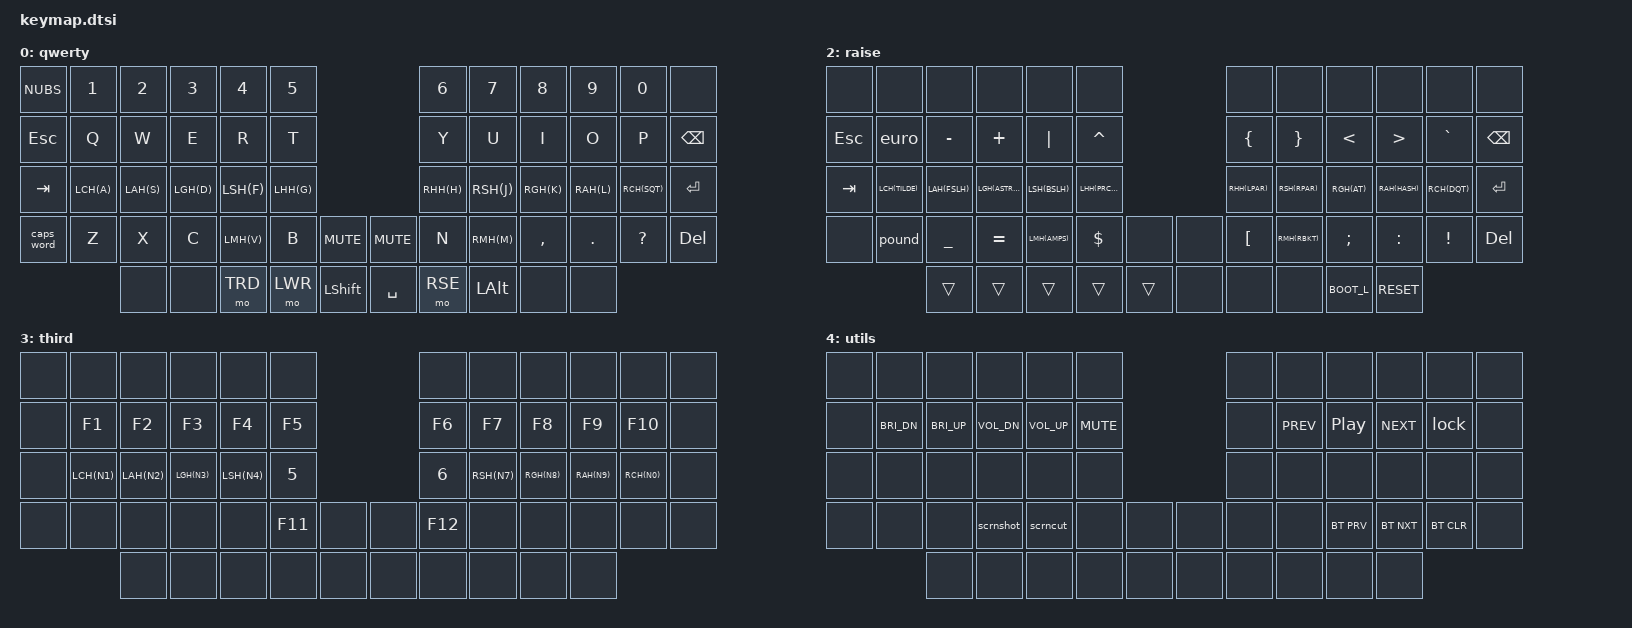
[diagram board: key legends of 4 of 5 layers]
/ {
    keymap {
        compatible = "zmk,keymap";
        qwerty {
            bindings = <
            /*╭───────────┬───────────┬───────────┬───────────┬───────────┬───────────╮                           ╭───────────┬───────────┬───────────┬───────────┬───────────┬───────────╮*/
            /*│     §     │     1     │     2     │     3     │     4     │     5     │                           │     6     │     7     │     8     │     9     │     0     │           │*/
                &kp NUBS    &kp N1      &kp N2      &kp N3      &kp N4      &kp N5    /*                         */ &kp N6      &kp N7      &kp N8      &kp N9      &kp N0      &none
            /*├───────────┼───────────┼───────────┼───────────┼───────────┼───────────┤                           ├───────────┼───────────┼───────────┼───────────┼───────────┼───────────┤*/
            /*│    esc    │     Q     │     W     │     E     │     R     │     T     │                           │     Y     │     U     │     I     │     O     │     P     │ backspace │*/
                &kp ESC     &kp Q       &kp W       &kp E       &kp R       &kp T     /*                         */ &kp Y       &kp U       &kp I       &kp O       &kp P       &kp BSPC
            /*├───────────┼───────────┼───────────┼───────────┼───────────┼───────────┤                           ├───────────┼───────────┼───────────┼───────────┼───────────┼───────────┤*/
            /*│    tab    │     A     │     S     │     D     │     F     │     G     ├───────────╮   ╭───────────┤     H     │     J     │     K     │     L     │     '     │   enter   │*/
                &kp TAB     LCH(A)      LAH(S)      LGH(D)      LSH(F)      LHH(G)    /* encoder */   /* encoder */ RHH(H)      RSH(J)      RGH(K)      RAH(L)      RCH(SQT)    &kp RET
            /*├───────────┼───────────┼───────────┼───────────┼───────────┼───────────┤           │   │           ├───────────┼───────────┼───────────┼───────────┼───────────┼───────────┤*/
            /*│ CAPS word │     Z     │     X     │     C     │     V     │     B     │   MUTE    │   │   MUTE    │     N     │     M     │     ,     │     .     │     ?     │  delete   │*/
                &caps_word  &kp Z       &kp X       &kp C       LMH(V)      &kp B       &kp MUTE  /* */ &kp MUTE    &kp N       RMH(M)      &kp COMMA   &kp DOT     &kp QMARK   &kp DEL
            /*╰───────────┴───────────┼───────────┼───────────┼───────────┼───────────┼───────────┤   ├───────────┼───────────┼───────────┼───────────┼───────────┼───────────┴───────────╯*/
            /*                        │           │           │           │           │   shift   │   │   space   │           │    alt    │           │           │                        */
                                        &none       &none       &mo TRD     &mo LWR     &kp LSHIFT/* */ &kp SPACE   &mo RSE     &kp LALT    &none       &none
            /*                        ╰───────────┴───────────┴───────────┴───────────┤           │   │           ├───────────┴───────────┴───────────┴───────────╯                        */
            /*                                                                        ╰───────────╯   ╰───────────╯                                                                        */
            >;

            sensor-bindings = <
                &inc_dec_kp BRI_DN BRI_UP &inc_dec_kp VOL_DN VOL_UP
            >;
        };
        lower {
            bindings = <
            /*╭───────────┬───────────┬───────────┬───────────┬───────────┬───────────╮                           ╭───────────┬───────────┬───────────┬───────────┬───────────┬───────────╮*/
            /*│           │           │           │           │           │           │                           │           │           │           │           │           │           │*/
                &none       &none       &none       &none       &none       &none     /*                         */ &none       &none       &none       &none       &none       &none
            /*├───────────┼───────────┼───────────┼───────────┼───────────┼───────────┤                           ├───────────┼───────────┼───────────┼───────────┼───────────┼───────────┤*/
            /*│           │           │           │           │           │           │                           │           │           │           │           │           │ backspace │*/
                &none       &kp BRI_DN  &kp BRI_UP  &kp VOL_DN  &kp VOL_UP  &kp MUTE  /*                         */ &none       &kp C_PREV  &kp C_PP    &kp C_NEXT  &lock       &kp BSPC
            /*├───────────┼───────────┼───────────┼───────────┼───────────┼───────────┤                           ├───────────┼───────────┼───────────┼───────────┼───────────┼───────────┤*/
            /*│           │    ctrl   │    alt    │    cmd    │   shift   │ CAPS word ├───────────╮   ╭───────────┤     <     │     v     │     ^     │     >     │           │   enter   │*/
                &none       &kp LCTRL   &kp LALT    &kp LGUI    &kp LSHIFT  &caps_word/* encoder */   /* encoder */ &kp LEFT    &kp DOWN    &kp UP      &kp RIGHT   &none       &kp RET
            /*├───────────┼───────────┼───────────┼───────────┼───────────┼───────────┤           │   │           ├───────────┼───────────┼───────────┼───────────┼───────────┼───────────┤*/
            /*│           │           │           │ screenshot│ screencut │           │           │   │           │ backspace │   enter   │    tab    │    esc    │   delete  │  delete   │*/
                &none       &none       &none       &scrnshot   &scrncut    RP          &none     /* */ &none       &kp BSPC    &kp RET     &kp TAB     &kp ESC     &kp DEL     &kp DEL
            /*╰───────────┴───────────┼───────────┼───────────┼───────────┼───────────┼───────────┤   ├───────────┼───────────┼───────────┼───────────┼───────────┼───────────┴───────────╯*/
            /*                        │   reset   │ bootloader│           │[activator]│           │   │   space   │           │           │           │           │                        */
                                        RESET       BOOT_L      &none       &none       &none     /* */ &kp SPACE   &trans      &trans      &trans      &trans
            /*                        ╰───────────┴───────────┴───────────┴───────────┤           │   │           ├───────────┴───────────┴───────────┴───────────╯                        */
            /*                                                                        ╰───────────╯   ╰───────────╯                                                                        */
            >;

            sensor-bindings = <
                &inc_dec_kp BRI_DN BRI_UP &inc_dec_kp VOL_DN VOL_UP
            >;
        };
        raise {
            bindings = <
            /*╭───────────┬───────────┬───────────┬───────────┬───────────┬───────────╮                           ╭───────────┬───────────┬───────────┬───────────┬───────────┬───────────╮*/
            /*│           │           │           │           │           │           │                           │           │           │           │           │           │           │*/
                &none       &none       &none       &none       &none       &none     /*                         */ &none       &none       &none       &none       &none       &none
            /*├───────────┼───────────┼───────────┼───────────┼───────────┼───────────┤                           ├───────────┼───────────┼───────────┼───────────┼───────────┼───────────┤*/
            /*│    esc    │     €     │     -     │     +     │     |     │     ^     │                           │     {     │     }     │     <     │     >     │     `     │ backspace │*/
                &kp ESC     &euro       &kp MINUS   &kp PLUS    &kp PIPE    &kp CARET /*                         */ &kp LBRC    &kp RBRC    &kp LT      &kp GT      &kp GRAVE   &kp BSPC
            /*├───────────┼───────────┼───────────┼───────────┼───────────┼───────────┤                           ├───────────┼───────────┼───────────┼───────────┼───────────┼───────────┤*/
            /*│    tab    │     ~     │     /     │     *     │     \     │     %     ├───────────╮   ╭───────────┤     (     │     )     │     @     │     #     │     "     │   enter   │*/
                &kp TAB     LCH(TILDE)  LAH(FSLH)   LGH(ASTRK)  LSH(BSLH)   LHH(PRCNT)/* encoder */   /* encoder */ RHH(LPAR)   RSH(RPAR)   RGH(AT)     RAH(HASH)   RCH(DQT)    &kp RET
            /*├───────────┼───────────┼───────────┼───────────┼───────────┼───────────┤           │   │           ├───────────┼───────────┼───────────┼───────────┼───────────┼───────────┤*/
            /*│           │     £     │     _     │     =     │     &     │     $     │           │   │           │     [     │     ]     │     ;     │     :     │     !     │  delete   │*/
                &none       &pound      &kp UNDER   &kp EQUAL   LMH(AMPS)   &kp DLLR    &none     /* */ &none       &kp LBKT    RMH(RBKT)   &kp SEMI    &kp COLON   &kp EXCL    &kp DEL
            /*╰───────────┴───────────┼───────────┼───────────┼───────────┼───────────┼───────────┤   ├───────────┼───────────┼───────────┼───────────┼───────────┼───────────┴───────────╯*/
            /*                        │           │           │           │           │           │   │           │[activator]│           │ bootloader│   reset   │                        */
                                        &trans      &trans      &trans      &trans      &trans    /* */ &none       &none       &none       BOOT_L      RESET
            /*                        ╰───────────┴───────────┴───────────┴───────────┤           │   │           ├───────────┴───────────┴───────────┴───────────╯                        */
            /*                                                                        ╰───────────╯   ╰───────────╯                                                                        */
            >;

            sensor-bindings = <
                &inc_dec_kp BRI_DN BRI_UP &inc_dec_kp C_PREV C_NEXT
            >;
        };
        third {
            bindings = <
            /*╭───────────┬───────────┬───────────┬───────────┬───────────┬───────────╮                           ╭───────────┬───────────┬───────────┬───────────┬───────────┬───────────╮*/
            /*│           │           │           │           │           │           │                           │           │           │           │           │           │           │*/
                &none       &none       &none       &none       &none       &none     /*                         */ &none       &none       &none       &none       &none       &none
            /*├───────────┼───────────┼───────────┼───────────┼───────────┼───────────┤                           ├───────────┼───────────┼───────────┼───────────┼───────────┼───────────┤*/
            /*│           │    F1     │    F2     │    F3     │    F4     │    F5     │                           │    F6     │    F7     │    F8     │    F9     │    F10    │           │*/
                &none       &kp F1      &kp F2      &kp F3      &kp F4      &kp F5    /*                         */ &kp F6      &kp F7      &kp F8      &kp F9      &kp F10     &none
            /*├───────────┼───────────┼───────────┼───────────┼───────────┼───────────┤                           ├───────────┼───────────┼───────────┼───────────┼───────────┼───────────┤*/
            /*│           │     1     │     2     │     3     │     4     │     5     ├───────────╮   ╭───────────┤     6     │     7     │     8     │     9     │     10    │           │*/
                &none       LCH(N1)     LAH(N2)     LGH(N3)     LSH(N4)     &kp N5    /* encoder */   /* encoder */ &kp N6      RSH(N7)     RGH(N8)     RAH(N9)     RCH(N0)     &none
            /*├───────────┼───────────┼───────────┼───────────┼───────────┼───────────┤           │   │           ├───────────┼───────────┼───────────┼───────────┼───────────┼───────────┤*/
            /*│           │           │           │           │           │    F11    │           │   │           │    F12    │           │           │           │           │           │*/
                &none       &none       &none       &none       &none       &kp F11     &none     /* */ &none       &kp F12     &none       &none       &none       &none       &none
            /*╰───────────┴───────────┼───────────┼───────────┼───────────┼───────────┼───────────┤   ├───────────┼───────────┼───────────┼───────────┼───────────┼───────────┴───────────╯*/
            /*                        │           │           │[activator]│           │           │   │           │           │           │           │           │                        */
                                        &none       &none       &none       &none       &none     /* */ &none       &none       &none       &none       &none
            /*                        ╰───────────┴───────────┴───────────┴───────────┤           │   │           ├───────────┴───────────┴───────────┴───────────╯                        */
            /*                                                                        ╰───────────╯   ╰───────────╯                                                                        */
            >;

            sensor-bindings = <
                &inc_dec_kp BRI_DN BRI_UP &inc_dec_kp VOL_DN VOL_UP
            >;
        };
        utils {
            bindings = <
            /*╭───────────┬───────────┬───────────┬───────────┬───────────┬───────────╮                           ╭───────────┬───────────┬───────────┬───────────┬───────────┬───────────╮*/
            /*│           │           │           │           │           │           │                           │           │           │           │           │           │           │*/
                &none       &none       &none       &none       &none       &none     /*                         */ &none       &none       &none       &none       &none       &none
            /*├───────────┼───────────┼───────────┼───────────┼───────────┼───────────┤                           ├───────────┼───────────┼───────────┼───────────┼───────────┼───────────┤*/
            /*│           │           │           │           │           │           │                           │           │           │           │           │           │           │*/
                &none       &kp BRI_DN  &kp BRI_UP  &kp VOL_DN  &kp VOL_UP  &kp MUTE  /*                         */ &none       &kp C_PREV  &kp C_PP    &kp C_NEXT  &lock       &none
            /*├───────────┼───────────┼───────────┼───────────┼───────────┼───────────┤                           ├───────────┼───────────┼───────────┼───────────┼───────────┼───────────┤*/
            /*│           │           │           │           │           │           ├───────────╮   ╭───────────┤           │           │           │           │           │           │*/
                &none       &none       &none       &none       &none       &none     /* encoder */   /* encoder */ &none       &none       &none       &none       &none       &none
            /*├───────────┼───────────┼───────────┼───────────┼───────────┼───────────┤           │   │           ├───────────┼───────────┼───────────┼───────────┼───────────┼───────────┤*/
            /*│           │           │           │ screenshot│ screencut │           │           │   │           │           │           │           │           │           │           │*/
                &none       &none       &none       &scrnshot   &scrncut    &none       &none     /* */ &none       &none       &none       &bt BT_PRV  &bt BT_NXT  &bt BT_CLR  &none
            /*╰───────────┴───────────┼───────────┼───────────┼───────────┼───────────┼───────────┤   ├───────────┼───────────┼───────────┼───────────┼───────────┼───────────┴───────────╯*/
            /*                        │           │           │           │[activator]│           │   │           │[activator]│           │           │           │                        */
                                        &none       &none       &none       &none       &none     /* */ &none       &none       &none       &none       &none
            /*                        ╰───────────┴───────────┴───────────┴───────────┤           │   │           ├───────────┴───────────┴───────────┴───────────╯                        */
            /*                                                                        ╰───────────╯   ╰───────────╯                                                                        */
            >;

            sensor-bindings = <
                &inc_dec_kp BRI_DN BRI_UP &inc_dec_kp VOL_DN VOL_UP
            >;
        };
            /*╭───────────┬───────────┬───────────┬───────────┬───────────┬───────────╮                           ╭───────────┬───────────┬───────────┬───────────┬───────────┬───────────╮*/
            /*│           │           │           │           │           │           │                           │           │           │           │           │           │           │*/
            /*├───────────┼───────────┼───────────┼───────────┼───────────┼───────────┤                           ├───────────┼───────────┼───────────┼───────────┼───────────┼───────────┤*/
            /*│           │           │           │           │           │           │                           │           │           │           │           │           │           │*/             
            /*├───────────┼───────────┼───────────┼───────────┼───────────┼───────────┤                           ├───────────┼───────────┼───────────┼───────────┼───────────┼───────────┤*/
            /*│           │           │           │           │           │           ├───────────╮   ╭───────────┤           │           │           │           │           │           │*/
            /*├───────────┼───────────┼───────────┼───────────┼───────────┼───────────┤           │   │           ├───────────┼───────────┼───────────┼───────────┼───────────┼───────────┤*/
            /*│           │           │           │           │           │           │           │   │           │           │           │           │           │           │           │*/
            /*╰───────────┴───────────┼───────────┼───────────┼───────────┼───────────┼───────────┤   ├───────────┼───────────┼───────────┼───────────┼───────────┼───────────┴───────────╯*/
            /*                        │           │           │           │           │           │   │           │           │           │           │           │                        */
            /*                        ╰───────────┴───────────┴───────────┴───────────┤           │   │           ├───────────┴───────────┴───────────┴───────────╯                        */
            /*                                                                        ╰───────────╯   ╰───────────╯                                                                        */
            /*                                                                                                                                                                             */
    };
};
